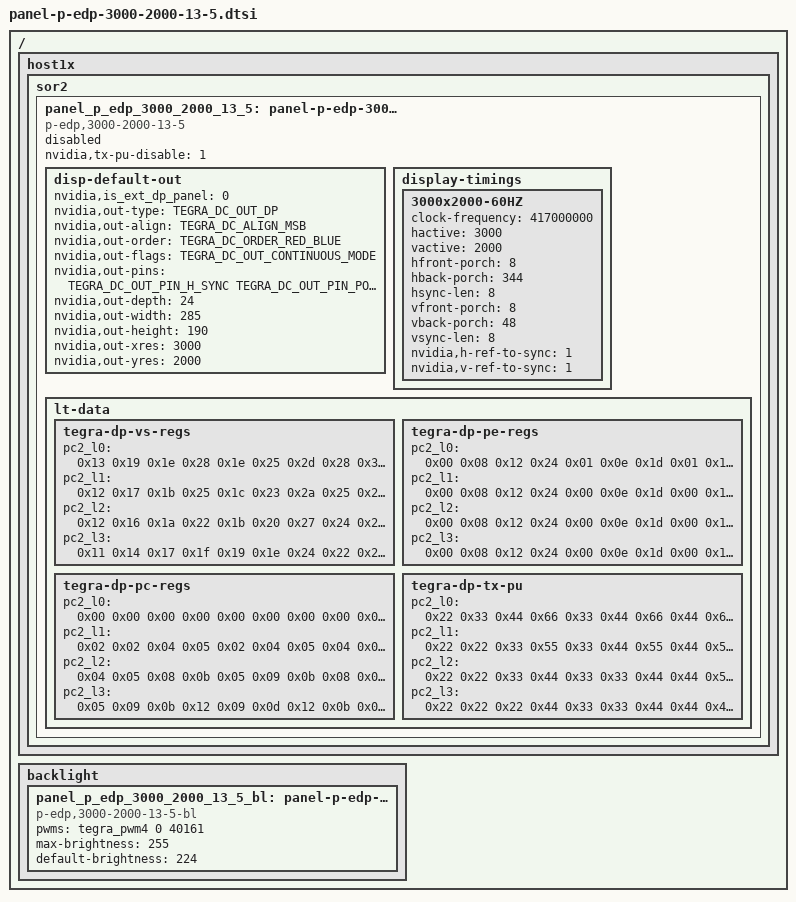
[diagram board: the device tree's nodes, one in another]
/*
 * arch/arm/boot/dts/panel-p-edp-3000-2000-13-5.dtsi
 *
 * Copyright (c) 2014-2018, NVIDIA CORPORATION.  All rights reserved.
 *
 * This program is free software; you can redistribute it and/or modify
 * it under the terms of the GNU General Public License as published by
 * the Free Software Foundation; either version 2 of the License, or
 * (at your option) any later version.
 *
 * This program is distributed in the hope that it will be useful, but WITHOUT
 * ANY WARRANTY; without even the implied warranty of MERCHANTABILITY or
 * FITNESS FOR A PARTICULAR PURPOSE.  See the GNU General Public License for
 * more details.
 *
 * You should have received a copy of the GNU General Public License along
 * with this program; if not, write to the Free Software Foundation, Inc.,
 * 51 Franklin Street, Fifth Floor, Boston, MA  02110-1301, USA.
 */
#include <dt-bindings/display/tegra-dc.h>
#include <dt-bindings/display/tegra-panel.h>

/ {
	host1x {
		sor2 {
			panel_p_edp_3000_2000_13_5: panel-p-edp-3000-2000-13-5 {
				status = "disabled";
				compatible = "p-edp,3000-2000-13-5";
				nvidia,tx-pu-disable = <1>;
				disp-default-out {
					nvidia,is_ext_dp_panel=<0>;
					nvidia,out-type = <TEGRA_DC_OUT_DP>;
					nvidia,out-align = <TEGRA_DC_ALIGN_MSB>;
					nvidia,out-order = <TEGRA_DC_ORDER_RED_BLUE>;
					nvidia,out-flags = <TEGRA_DC_OUT_CONTINUOUS_MODE>;
					nvidia,out-pins = <TEGRA_DC_OUT_PIN_H_SYNC TEGRA_DC_OUT_PIN_POL_LOW
							   TEGRA_DC_OUT_PIN_V_SYNC TEGRA_DC_OUT_PIN_POL_LOW
							   TEGRA_DC_OUT_PIN_PIXEL_CLOCK TEGRA_DC_OUT_PIN_POL_LOW
							   TEGRA_DC_OUT_PIN_DATA_ENABLE TEGRA_DC_OUT_PIN_POL_HIGH>;
					nvidia,out-depth = <24>;
					nvidia,out-width = <285>;
					nvidia,out-height = <190>;
					nvidia,out-xres = <3000>;
					nvidia,out-yres = <2000>;
				};
				display-timings {
					3000x2000-60HZ {
						clock-frequency = <417000000>;
						hactive = <3000>;
						vactive = <2000>;
						hfront-porch = <8>;
						hback-porch = <344>;
						hsync-len = <8>;
						vfront-porch = <8>;
						vback-porch = <48>;
						vsync-len = <8>;
						nvidia,h-ref-to-sync = <1>;
						nvidia,v-ref-to-sync = <1>;
					};
				};
				lt-data {
					tegra-dp-vs-regs {
						/* postcursor2 L0 */
						pc2_l0 = <
							/* pre-emphasis: L0, L1, L2, L3 */
							0x13 0x19 0x1e 0x28 /* voltage swing: L0 */
							0x1e 0x25 0x2d /* L1 */
							0x28 0x32 /* L2 */
							0x39 /* L3 */
						>;
						/* postcursor2 L1 */
						pc2_l1 = <
							0x12 0x17 0x1b 0x25
							0x1c 0x23 0x2a
							0x25 0x2f
							0x37
						>;
						/* postcursor2 L2 */
						pc2_l2 = <
							0x12 0x16 0x1a 0x22
							0x1b 0x20 0x27
							0x24 0x2d
							0x35
						>;
						/* postcursor2 L3 */
						pc2_l3 = <
							0x11 0x14 0x17 0x1f
							0x19 0x1e 0x24
							0x22 0x2a
							0x32
						>;
					};
					tegra-dp-pe-regs {
						/* postcursor2 L0 */
						pc2_l0 = <
							/* pre-emphasis: L0, L1, L2, L3 */
							0x00 0x08 0x12 0x24 /* voltage swing: L0 */
							0x01 0x0e 0x1d /* L1 */
							0x01 0x13 /* L2 */
							0x00 /* L3 */
						>;
						/* postcursor2 L1 */
						pc2_l1 = <
							0x00 0x08 0x12 0x24
							0x00 0x0e 0x1d
							0x00 0x13
							0x00
						>;
						/* postcursor2 L2 */
						pc2_l2 = <
							0x00 0x08 0x12 0x24
							0x00 0x0e 0x1d
							0x00 0x13
							0x00
						>;
						/* postcursor2 L3 */
						pc2_l3 = <
							0x00 0x08 0x12 0x24
							0x00 0x0e 0x1d
							0x00 0x13
							0x00
						>;
					};
					tegra-dp-pc-regs {
						/* postcursor2 L0 */
						pc2_l0 = <
							/* pre-emphasis: L0, L1, L2, L3 */
							0x00 0x00 0x00 0x00 /* voltage swing: L0 */
							0x00 0x00 0x00 /* L1 */
							0x00 0x00 /* L2 */
							0x00 /* L3 */
						>;
						/* postcursor2 L1 */
						pc2_l1 = <
							0x02 0x02 0x04 0x05
							0x02 0x04 0x05
							0x04 0x05
							0x05
						>;
						/* postcursor2 L2 */
						pc2_l2 = <
							0x04 0x05 0x08 0x0b
							0x05 0x09 0x0b
							0x08 0x0a
							0x0b
						>;
						/* postcursor2 L3 */
						pc2_l3 = <
							0x05 0x09 0x0b 0x12
							0x09 0x0d 0x12
							0x0b 0x0f
							0x12
						>;
					};
					tegra-dp-tx-pu {
						/* postcursor2 L0 */
						pc2_l0 = <
							/* pre-emphasis: L0, L1, L2, L3 */
							0x22 0x33 0x44 0x66 /* voltage swing: L0 */
							0x33 0x44 0x66 /* L1 */
							0x44 0x66 /* L2 */
							0x66 /* L3 */
						>;
						/* postcursor2 L1 */
						pc2_l1 = <
							0x22 0x22 0x33 0x55
							0x33 0x44 0x55
							0x44 0x55
							0x66
						>;
						/* postcursor2 L2 */
						pc2_l2 = <
							0x22 0x22 0x33 0x44
							0x33 0x33 0x44
							0x44 0x55
							0x66
						>;
						/* postcursor2 L3 */
						pc2_l3 = <
							0x22 0x22 0x22 0x44
							0x33 0x33 0x44
							0x44 0x44
							0x66
						>;
					};
				};
			};
		};
	};
	backlight {
		panel_p_edp_3000_2000_13_5_bl: panel-p-edp-3000-2000-13-5-bl {
			status = "okay";
			compatible = "p-edp,3000-2000-13-5-bl";
			pwms = <&tegra_pwm4 0 40161>;
			max-brightness = <255>;
			default-brightness = <224>;
		};
	};
};
